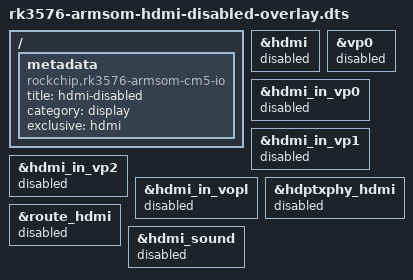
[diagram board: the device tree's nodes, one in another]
/dts-v1/;
/plugin/;

#include <dt-bindings/gpio/gpio.h>
#include <dt-bindings/pinctrl/rockchip.h>
#include <dt-bindings/display/drm_mipi_dsi.h>
#include <dt-bindings/interrupt-controller/irq.h>

/ {
    metadata {
        title = "hdmi-disabled";
        category = "display";
        compatible = "rockchip,rk3576-armsom-cm5-io", "rockchip,rk3588-armsom-sige5";
        exclusive = "hdmi";
    };

    fragment@0 {
        target = <&hdmi>;

        __overlay__ {
            status = "disabled";
        };
    };

    fragment@1 {
        target = <&vp0>;

        __overlay__ {
            status = "disabled";
        };
    };

    fragment@2 {
        target = <&hdmi_in_vp0>;

        __overlay__ {
            status = "disabled";
        };
    };

    fragment@3 {
        target = <&hdmi_in_vp1>;

        __overlay__ {
            status = "disabled";
        };
    };

    fragment@4 {
        target = <&hdmi_in_vp2>;

        __overlay__ {
            status = "disabled";
        };
    };

    fragment@5 {
        target = <&hdmi_in_vopl>;

        __overlay__ {
            status = "disabled";
        };
    };

    fragment@6 {
        target = <&hdptxphy_hdmi>;

        __overlay__ {
            status = "disabled";
        };
    };

    fragment@7 {
        target = <&route_hdmi>;

        __overlay__ {
            status = "disabled";
        };
    };

    fragment@8 {
        target = <&hdmi_sound>;

        __overlay__ {
            status = "disabled";
        };
    };
};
